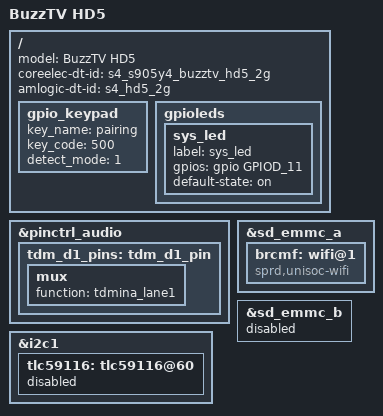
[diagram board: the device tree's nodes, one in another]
#include "s4_s905y4_ap222_linux.dts"
#include "coreelec_s4_common.dtsi"

/ {
	model = "BuzzTV HD5";
	coreelec-dt-id = "s4_s905y4_buzztv_hd5_2g";
	amlogic-dt-id = "s4_hd5_2g";

	gpio_keypad{
		key_name = "pairing";
		key_code = <500>;
		detect_mode = <1>;/*0:polling mode, 1:irq mode*/
	};

	gpioleds {
		sys_led {
			label = "sys_led";
			gpios = <&gpio GPIOD_11 GPIO_ACTIVE_HIGH>;
			default-state = "on";
		};
	};

	/delete-node/ dvb-extern;
	/delete-node/ dvb-demux;
	/delete-node/ aml_dtv_demod;
	/delete-node/ adc_keypad;
};

&pinctrl_audio {
	tdm_d1_pins: tdm_d1_pin {
		mux {
			function = "tdmina_lane1";
		};
	};
};

&sd_emmc_a {
	/delete-property/ use_intf3_tuning;
	brcmf: wifi@1 {
		compatible = "sprd,unisoc-wifi";
	};
};

&sd_emmc_b {
	status = "disabled";
};

&i2c1 {
	tlc59116: tlc59116@60 {
		status = "disabled";
	};
};
